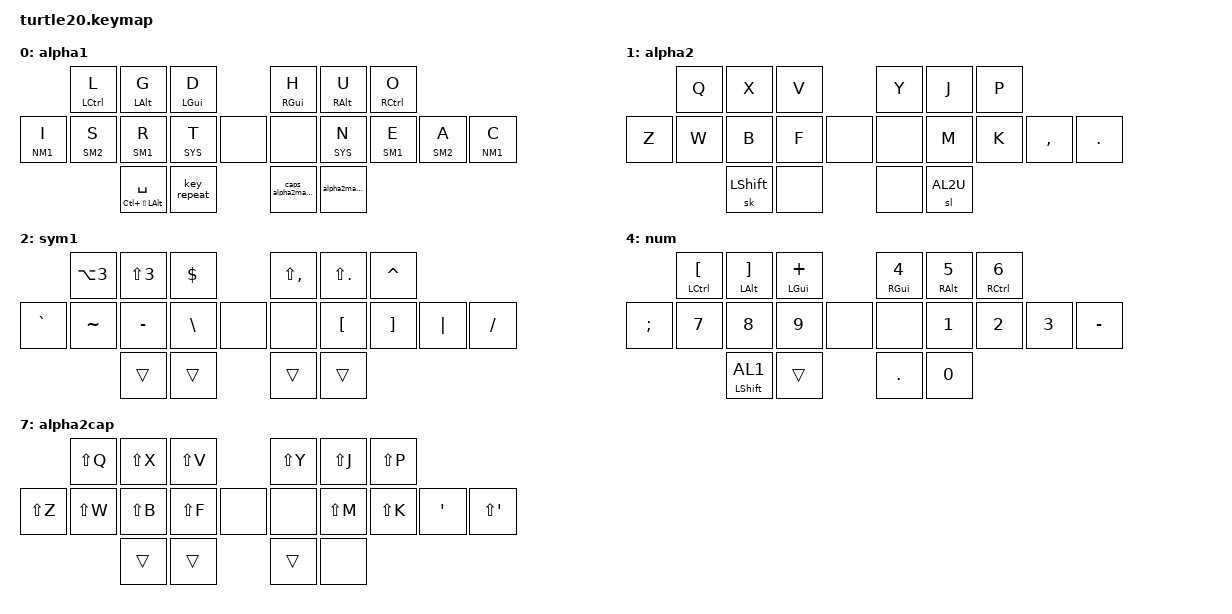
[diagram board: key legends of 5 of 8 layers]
/*
 * Copyright (c) 2020 The ZMK Contributors
 *
 * SPDX-License-Identifier: MIT
 */

#include <behaviors.dtsi>
#include <dt-bindings/zmk/keys.h>
#include <dt-bindings/zmk/bt.h>
#include <dt-bindings/zmk/mouse.h>



&mt {
    tapping-term-ms = <201>;
    flavor = "tap-preferred";
 };
&sk {
     release-after-ms = <2000>;
     quick-release;
 };
 
/* Layers */
#define AL1 0
#define AL2 1
#define SM1 2
#define SM2 3	
#define NM1 4	
#define SYS 5
#define BT 6	
#define AL2U 7
/ {
combos {
	compatible = "zmk,combos";
	combo_bkspc {
	    timeout-ms = <30>;
        key-positions = <13 14>;
        bindings = <&kp BKSP>;
	};
    combo_enter {
        timeout-ms = <30>;
        key-positions = <4 5>;
        bindings = <&kp RET>;
    };
    combo_tab {
        timeout-ms = <30>;
        key-positions = <0 1>;
        bindings = <&kp TAB>;
    };
    combo_esc {
        timeout-ms = <30>;
        key-positions = <7 8>;
        bindings = <&kp ESC>;
    };
};
/*
    combos {
        compatible = "zmk,combos";
        combo_sys {
            timeout-ms = <30>;
	    key-positions = <3 4 5>;
            bindings = <&to SYS>;
        };
        combo_caps {
            timeout-ms = <30>;
	    key-positions = <10 11 12>;
            bindings = <&caps_word>;
        };
        combo_bt  {
            timeout-ms = <10>;
            key-positions = <11 12>;
            bindings = <&to BT>;
	    layers = <SM1>; 
        };
        lalt {
            timeout-ms = <20>;
	    key-positions = <8 9>;
            bindings = <&kp LALT>; 
	    layers = <SYS>; 
        };
        lclk {
            timeout-ms = <20>;
	    key-positions = <10 11>;
            bindings = <&mkp LCLK>;
	    layers = <SYS>;
        };
        rclk {
            timeout-ms = <20>;
	    key-positions = <3 4>;
            bindings = <&mkp RCLK>;
	    layers = <SYS>;
        };


    };
*/
    behaviors {
        hm_l: homerow_mods_left {
            compatible = "zmk,behavior-hold-tap";
            label = "HOMEROW_MODS_L";
            #binding-cells = <2>;
            tapping-term-ms = <300>;
            quick-tap-ms = <250>;
            flavor = "tap-preferred";
            bindings = <&kp>, <&kp>;
	    hold-trigger-key-positions = <3 4 5 10 11 12 13 14>; // right hand
        };
        hm_r: homerow_mods_right {
            compatible = "zmk,behavior-hold-tap";
            label = "HOMEROW_MODS_R";
            #binding-cells = <2>;
            tapping-term-ms = <300>;
            quick-tap-ms = <250>;
            flavor = "tap-preferred";
            bindings = <&kp>, <&kp>;
	    hold-trigger-key-positions = <0 1 2 6 7 8 9>; // left hand
        };
        sr: shift_layer {
            compatible = "zmk,behavior-hold-tap";
            label = "SHIFT_LAYER";
            #binding-cells = <2>;
            tapping-term-ms = <300>;
            quick_tap_ms = <0>;
            flavor = "tap-preferred";
            bindings = <&kp>, <&to>;
	    retro-tap;
        };
        hl_l: homerow_layers_left {
            compatible = "zmk,behavior-hold-tap";
            label = "HOMEROW_LAYERS_L";
            #binding-cells = <2>;
            tapping-term-ms = <220>;
            quick-tap-ms = <250>;
            flavor = "tap-preferred";
            bindings = <&mo>, <&kp>;
	    hold-trigger-key-positions = <3 4 5 10 11 12 13 14>; // right hand
        };
        hl_r: homerow_layers_right {
            compatible = "zmk,behavior-hold-tap";
            label = "HOMEROW_LAYERS_R";
            #binding-cells = <2>;
            tapping-term-ms = <220>;
            quick-tap-ms = <250>;
            flavor = "tap-preferred";
            bindings = <&mo>, <&kp>;
	    hold-trigger-key-positions = <0 1 2 6 7 8 9>; // left hand
        };
	td: tapdance {
            compatible = "zmk,behavior-hold-tap";
            label = "TAPDANCE";
            #binding-cells = <2>;
            tapping-term-ms = <190>;
            quick-tap-ms = <250>;
            flavor = "tap-preferred";
            bindings = <&kp>, <&kp>;
        };
	alpha2macro: behavior_macro_1 {
		compatible = "zmk,behavior-macro";
		label = "MACRO1";
		#binding-cells = <0>;
		bindings = < &sl AL2 >;
	};
	caps_alpha2macro: behavior_macro_2 {
		compatible = "zmk,behavior-macro";
		label = "MACRO2";
		#binding-cells = <0>;
		bindings = < &sl AL2U >;
	};
    };
// 				0		1		2					3		4			5
// 		6		7		8		9 	10			11	12		13			14 		15
//								16	17 	18 	19		
       keymap {
                compatible = "zmk,keymap";
                
       		alpha1 {
		bindings = <
		 		&hm_l LCTL L 	&hm_l LALT G 	&hm_l LGUI D		&hm_r RGUI H 	&hm_r RALT U    	&hm_r RCTL O	  
		&hl_l NM1 I	&hl_l SM2 S	&hl_l SM1 R	&hl_l SYS T &none       &none	 	&hl_r SYS N    	&hl_r SM1 E   		&hl_r SM2 A 	&hl_r NM1 C
			 	 		 		&mt LC(LS(LALT)) SPC &key_repeat  &caps_alpha2macro	&alpha2macro	 	
		>;
		};
       		alpha2 {
		bindings = <
		 	 	&kp Q 		&kp X		&kp V	 	 	&kp Y    	&kp J			&kp P 		
		&kp Z	 	&kp W 		&kp B		&kp F 	&none		&none  &kp M 		&kp K			&kp COMMA	&kp DOT 
			 	 		 		&sk LSHIFT 		&none &none &sl AL2U	
		>;
		};
		
       		sym1 {
		bindings = <
		 		&kp LA(N3)   	&kp LS(N3)	&kp DLLR	    	&kp LS(COMMA)	&kp LS(DOT)		&kp CARET	
		&kp GRAVE	&kp TILDE 	&kp MINUS      	&kp BSLH &none &none	 	&kp LBKT	&kp RBKT	 	&kp PIPE 	&kp SLASH
				  				&trans  		&trans		&trans  	&trans
		>;
		};
		sym2 {
		bindings = <
				&kp ATSN	&td LA(RBKT) LA(LS(RBKT))	&td  LA(LBKT) LA(LS(LBKT))	&kp LPRN	&kp RPRN 	&kp SEMI 	
		&kp STAR  	&kp PRCNT	&td QMARK EXCL       		&kp DQT   	&none &none		&kp LBRC  	&kp RBRC	&kp AMPS	&kp COLON 
		 		&trans 		&trans  			&trans 	&none &none &trans 		

		>;
		};

		num {
		bindings = <
				&hm_l LCTL LBKT 	&hm_l LALT RBKT	&hm_l LGUI PLUS 		&hm_r RGUI N4 	&hm_r RALT N5		&hm_r RCTL N6	
		&kp SEMI	&kp N7 	&kp N8		&kp N9	&none &none		&kp N1		&kp N2			&kp N3   	&kp MINUS
							&sr LSHIFT AL1 		&trans 		&kp DOT 			&kp N0  	 
		>;
		};

		sys {
		bindings = <
				 	&kp ESC			&kp LC(LS(TAB)) 	&kp RC(TAB)		&td LG(V) LG(C) 	&kp UP 		&td Q BKSP 			
		&td LG(GRAVE) TAB	&td HOME DEL		&td END LG(LBKT) &none &none	&kp LG(RBKT)		&td TAB LEFT  		&kp DOWN 	&td  LC(LG(LS(N4))) RIGHT 	&kp RET 
		 			 		 				&sr LSHIFT AL1 		&none &none &kp RGUI		
		>;
		};

		bt {
		bindings = <
				&bt BT_PRV	&bt BT_NXT	&trans 			&trans 	&trans	&trans	
		&bootloader  	&trans 		&trans 		&trans 			&trans 	&trans 	&trans	&bt BT_CLR
		 	 	 				&to AL1	&none &none	&none
		>;
		};

       		alpha2cap {
		bindings = <
		 	 	&kp LS(Q)	&kp LS(X)	&kp LS(V) 	 	&kp LS(Y)    	&kp LS(J)		&kp LS(P)	
		&kp LS(Z) 	&kp LS(W) 	&kp LS(B)	&kp LS(F) &none &none	&kp LS(M)	&kp LS(K)	&kp SQT	&kp LS(SQT) 
			 	&trans 		&trans 			&trans	&none
		>;
		};
        
	};
};

